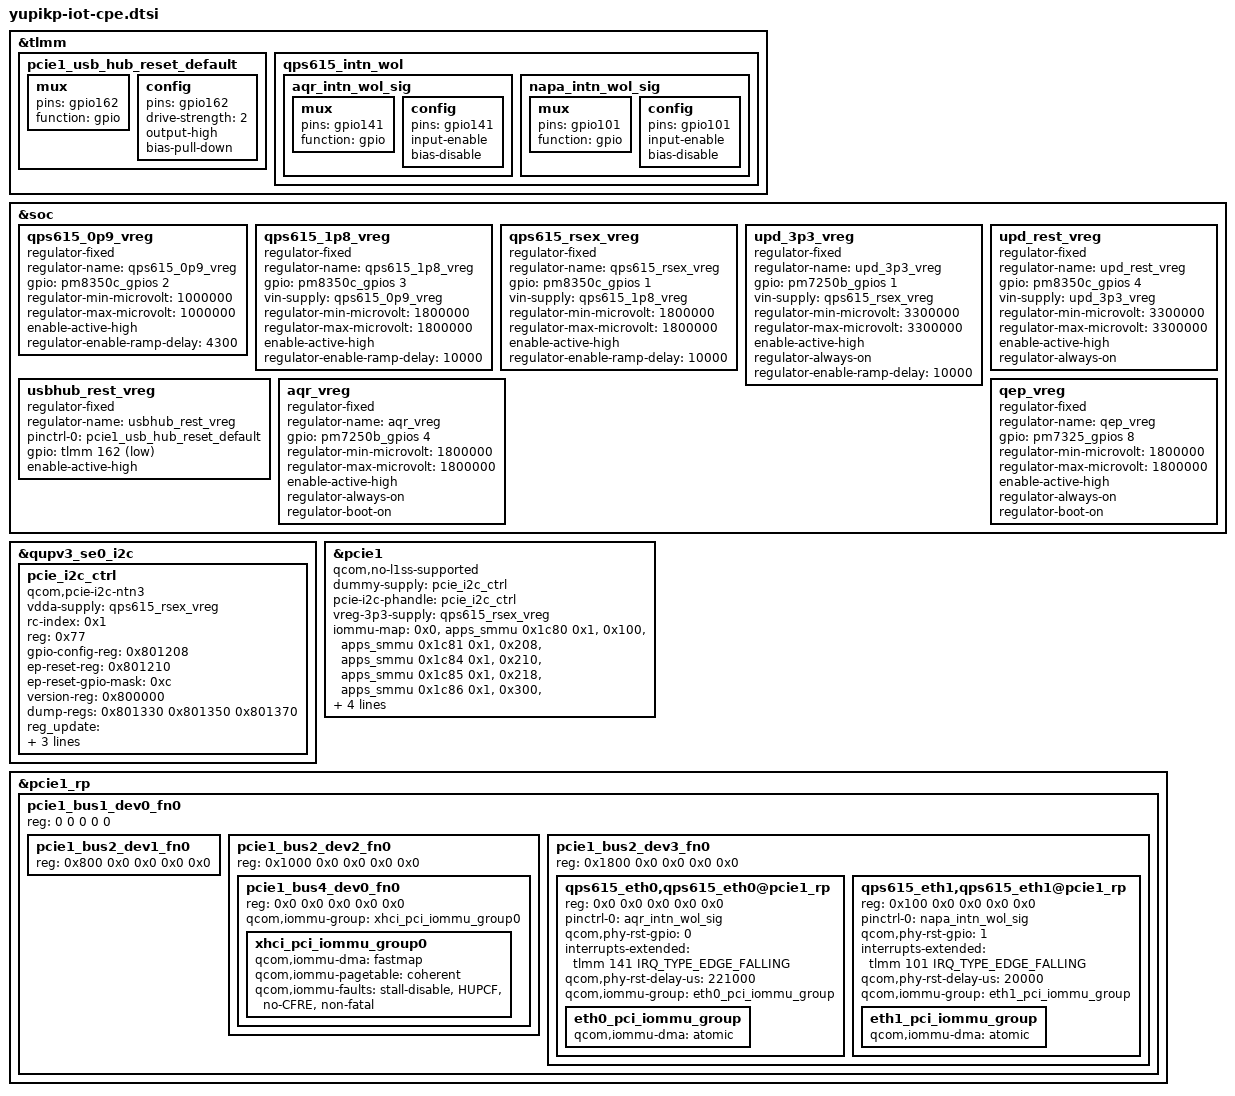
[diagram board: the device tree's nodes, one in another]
// SPDX-License-Identifier: BSD-3-Clause
/*
 * Copyright (c) Qualcomm Technologies, Inc. and/or its subsidiaries.
 */

&tlmm {
	pcie1_usb_hub_reset_default: pcie1_usb_hub_reset_default {
		mux {
			pins = "gpio162";
			function = "gpio";
		};

		config {
			pins = "gpio162";
			drive-strength = <2>;
			output-high;
			bias-pull-down;
		};
	};

	qps615_intn_wol {
		aqr_intn_wol_sig: aqr_intn_wol_sig {
			mux {
				pins = "gpio141";
				function = "gpio";
			};

			config {
				pins = "gpio141";
				input-enable;
				bias-disable;
			};
		};

		napa_intn_wol_sig: napa_intn_wol_sig {
			mux {
				pins = "gpio101";
				function = "gpio";
			};

			config {
				pins = "gpio101";
				input-enable;
				bias-disable;
			};
		};
	};
};

&soc {
	qps615_0p9_vreg: qps615_0p9_vreg {
		compatible = "regulator-fixed";
		regulator-name = "qps615_0p9_vreg";
		gpio = <&pm8350c_gpios 2 0>;
		regulator-min-microvolt = <1000000>;
		regulator-max-microvolt = <1000000>;
		enable-active-high;
		regulator-enable-ramp-delay = <4300>;
	};

	qps615_1p8_vreg: qps615_1p8_vreg {
		compatible = "regulator-fixed";
		regulator-name = "qps615_1p8_vreg";
		gpio = <&pm8350c_gpios 3 0>;
		vin-supply = <&qps615_0p9_vreg>;
		regulator-min-microvolt = <1800000>;
		regulator-max-microvolt = <1800000>;
		enable-active-high;
		regulator-enable-ramp-delay = <10000>;
	};

	qps615_rsex_vreg: qps615_rsex_vreg {
		compatible = "regulator-fixed";
		regulator-name = "qps615_rsex_vreg";
		gpio = <&pm8350c_gpios 1 0>;
		vin-supply = <&qps615_1p8_vreg>;
		regulator-min-microvolt = <1800000>;
		regulator-max-microvolt = <1800000>;
		enable-active-high;
		regulator-enable-ramp-delay = <10000>;
	};

	upd_3p3_vreg: upd_3p3_vreg {
		compatible = "regulator-fixed";
		regulator-name = "upd_3p3_vreg";
		gpio = <&pm7250b_gpios 1 0>;
		vin-supply = <&qps615_rsex_vreg>;
		regulator-min-microvolt = <3300000>;
		regulator-max-microvolt = <3300000>;
		enable-active-high;
		regulator-always-on;
		regulator-enable-ramp-delay = <10000>;
	};

	upd_rest_vreg: upd_rest_vreg {
		compatible = "regulator-fixed";
		regulator-name = "upd_rest_vreg";
		gpio = <&pm8350c_gpios 4 0>;
		vin-supply = <&upd_3p3_vreg>;
		regulator-min-microvolt = <3300000>;
		regulator-max-microvolt = <3300000>;
		enable-active-high;
		regulator-always-on;
	};

	usbhub_rest_vreg: usbhub_rest_vreg {
		compatible = "regulator-fixed";
		regulator-name = "usbhub_rest_vreg";
		pinctrl-names = "default";
		pinctrl-0 = <&pcie1_usb_hub_reset_default>;
		gpio = <&tlmm 162 GPIO_ACTIVE_LOW>;
		enable-active-high;
	};

	aqr_vreg: aqr_vreg {
		compatible = "regulator-fixed";
		regulator-name = "aqr_vreg";
		gpio = <&pm7250b_gpios 4 0>;
		regulator-min-microvolt = <1800000>;
		regulator-max-microvolt = <1800000>;
		enable-active-high;
		regulator-always-on;
		regulator-boot-on;
	};

	qep_vreg: qep_vreg {
		compatible = "regulator-fixed";
		regulator-name = "qep_vreg";
		gpio = <&pm7325_gpios 8 0>;
		regulator-min-microvolt = <1800000>;
		regulator-max-microvolt = <1800000>;
		enable-active-high;
		regulator-always-on;
		regulator-boot-on;
	};
};

&qupv3_se0_i2c {
	status = "ok";
	pcie_i2c_ctrl: pcie_i2c_ctrl {
		compatible = "qcom,pcie-i2c-ntn3";
		vdda-supply = <&qps615_rsex_vreg>;
		rc-index = <0x1>;
		reg = <0x77>;
		gpio-config-reg = <0x801208>;
		ep-reset-reg = <0x801210>;
		ep-reset-gpio-mask = <0xc>;
		version-reg = <0x800000>;
		dump-regs = <0x801330 0x801350 0x801370>;
		reg_update = <0x82c030 0x1
					0x828000 0x3
					0x82bd00 0x8
					0x82c030 0x2
					0x828000 0x3
					0x82bd00 0x8
					0x82c030 0x8
					0x828000 0x1
					0x82bd00 0x8
					0x82c01c 0x10
					0x82c030 0xf
					0x828000 0xf
					0x82b268 0x2>;
		/*FOM for preset caluclation*/
		switch_reg_update = <0x82c02c 0x00000007
					0x824a10 0x00000001
					0x82c030 0x00000008
					0x828000 0x00000001
					0x82b074 0x00000020
					0x82b2bc 0x00000001>;
	};
};

&pcie1 {
	qcom,no-l1ss-supported;
	dummy-supply = <&pcie_i2c_ctrl>;
	pcie-i2c-phandle = <&pcie_i2c_ctrl>;
	vreg-3p3-supply = <&qps615_rsex_vreg>;
	iommu-map = <0x0 &apps_smmu 0x1c80 0x1>,
		    <0x100 &apps_smmu 0x1c81 0x1>,
		    <0x208 &apps_smmu 0x1c84 0x1>,
		    <0x210 &apps_smmu 0x1c85 0x1>,
		    <0x218 &apps_smmu 0x1c86 0x1>,
		    <0x300 &apps_smmu 0x1c87 0x1>,
		    <0x400 &apps_smmu 0x1c88 0x1>,
		    <0x500 &apps_smmu 0x1c8c 0x1>,
		    <0x501 &apps_smmu 0x1c8e 0x1>;
};

&pcie1_rp {
	#address-cells = <5>;
	#size-cells = <0>;

	/* BDF 1.0.0 */
	pcie1_bus1_dev0_fn0: pcie1_bus1_dev0_fn0 {
		reg = <0 0 0 0 0>;

		/* BDF 2.1.0 */
		pcie1_bus2_dev1_fn0: pcie1_bus2_dev1_fn0 {
			reg = <0x800 0x0 0x0 0x0 0x0>;
		};

		/* BDF 2.2.0 */
		pcie1_bus2_dev2_fn0: pcie1_bus2_dev2_fn0 {
			reg = <0x1000 0x0 0x0 0x0 0x0>;

			/* BDF 4.0.0 */
			pcie1_bus4_dev0_fn0: pcie1_bus4_dev0_fn0 {
				reg = <0x0 0x0 0x0 0x0 0x0>;

				qcom,iommu-group = <&xhci_pci_iommu_group0>;
				#address-cells = <1>;
				#size-cells = <1>;

				xhci_pci_iommu_group0: xhci_pci_iommu_group0 {
					qcom,iommu-dma = "fastmap";
					qcom,iommu-pagetable = "coherent";
					qcom,iommu-faults = "stall-disable", "HUPCF", "no-CFRE", "non-fatal";
				};
			};
		};

		/* BDF 2.3.0 */
		pcie1_bus2_dev3_fn0: pcie1_bus2_dev3_fn0 {
			reg = <0x1800 0x0 0x0 0x0 0x0>;
			qps615_eth0,qps615_eth0@pcie1_rp {
				reg = <0x0 0x0 0x0 0x0 0x0>;

				pinctrl-names = "default";
				pinctrl-0 = <&aqr_intn_wol_sig>;

				qcom,phy-rst-gpio = <0>;

				interrupts-extended = <&tlmm 141 IRQ_TYPE_EDGE_FALLING>;
				interrupt-names = "wol_irq";

				qcom,phy-rst-delay-us = <221000>;
				#address-cells = <1>;
				#size-cells = <1>;

				qcom,iommu-group = <&eth0_pci_iommu_group>;
				eth0_pci_iommu_group: eth0_pci_iommu_group {
					qcom,iommu-dma = "atomic";
				};
			};

			qps615_eth1,qps615_eth1@pcie1_rp {
				reg = <0x100 0x0 0x0 0x0 0x0>;

				pinctrl-names = "default";
				pinctrl-0 = <&napa_intn_wol_sig>;

				qcom,phy-rst-gpio = <1>;

				interrupts-extended = <&tlmm 101 IRQ_TYPE_EDGE_FALLING>;
				interrupt-names = "wol_irq";

				qcom,phy-rst-delay-us = <20000>;
				#address-cells = <1>;
				#size-cells = <1>;

				qcom,iommu-group = <&eth1_pci_iommu_group>;
				eth1_pci_iommu_group: eth1_pci_iommu_group {
					qcom,iommu-dma = "atomic";
				};
			};
		};
	};
};
